# S32R372 register map
Vendor: Freescale Semiconductor, Inc.; Series: Qorivva; File version: 1.6
Registers are 32-bit, read-write, reset 0x0 unless marked. A register's access mark holds for its fields unless they carry their own. Offsets are from the block's base; [hi:lo] are bit positions; {n}, {i} and the like mark numbered series; 'fields as' and 'values as' point back to an identical list.

## MEMU
Base 0xFFF50000; register names take the prefix MEMU_
0x00 CTRL — Control register
  [15] SWR — Software Reset bit
    0=No reset; 1=Reset asserted
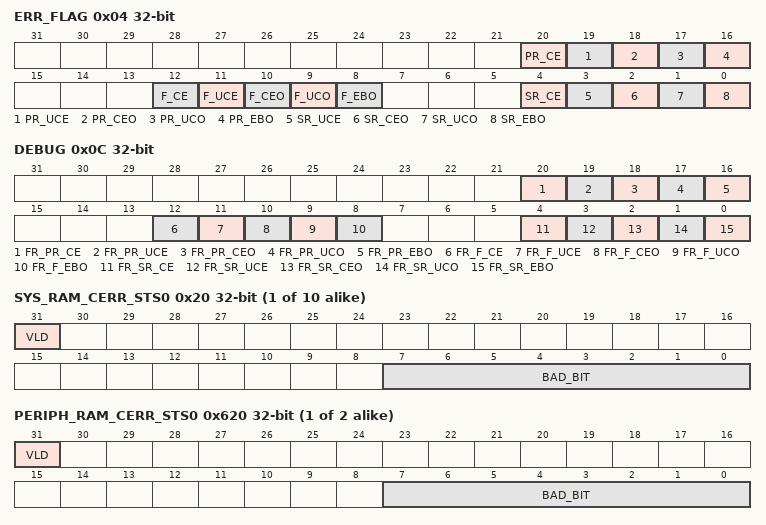
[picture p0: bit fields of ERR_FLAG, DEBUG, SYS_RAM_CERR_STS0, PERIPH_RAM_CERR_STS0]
0x04 ERR_FLAG — Error flag register
  [20] PR_CE — Peripheral RAM ECC Correctable Error detect flag
    0=No new and unique error detected; 1=New entry in correctable error reporting table is made
  [19] PR_UCE — Peripheral RAM ECC Uncorrectable Error Detect flag
    0=No new and unique error detected; 1=New entry in uncorrectable error reporting table is made
  [18] PR_CEO — Peripheral RAM ECC Correctable error Overflow flag
    0=No Overflow; 1=Overflow in the correctable error reporting table detected
  [17] PR_UCO — Peripheral RAM ECC Uncorrectable error Overflow flag
    0=No Overflow; 1=Overflow in the uncorrectable error reporting table detected
  [16] PR_EBO — Peripheral RAM ECC Error buffer Overflow flag
  [12] F_CE — Flash ECC Correctable Error Detect flag
    values as PR_CE
  [11] F_UCE — Flash ECC Uncorrectable Error Detect flag
    values as PR_UCE
  [10] F_CEO — Flash ECC Correctable Error Overflow flag
    values as PR_CEO
  [9] F_UCO — Flash ECC Uncorrectable Error Overflow flag
    values as PR_UCO
  [8] F_EBO — Flash ECC Error buffer Overflow
    0=No Overflow; 1=Overflow in the internal error processing buffer detected
  [4] SR_CE — System RAM ECC Correctable Error detect flag
    values as PR_CE
  [3] SR_UCE — System RAM ECC Uncorrectable Error Detect flag
    values as PR_UCE
  [2] SR_CEO — System RAM ECC Correctable error Overflow flag
    values as PR_CEO
  [1] SR_UCO — System RAM ECC Uncorrectable error Overflow flag
    values as PR_UCO
  [0] SR_EBO — System RAM ECC Error buffer Overflow
    values as F_EBO
0x0C DEBUG
  [20] FR_PR_CE — Force Peripheral RAM Correctable Error detect flag.
    0=Forcing is disabled; 1=Forces PR_CE flag going towards FCCU to 1
  [19] FR_PR_UCE — Force Peripheral RAM Uncorrectable Error detect flag.
    0=Forcing is disabled; 1=Forces PR_UCE flag going towards FCCU to 1
  [18] FR_PR_CEO — Force Peripheral RAM Correctable Error overflow flag
    0=Forcing is disabled; 1=Forces PR_CEO flag going towards FCCU to 1
  [17] FR_PR_UCO — Forces Peripheral RAM Uncorrectable Error overflow flag.
    0=Forcing is disabled; 1=Forces PR_UCO flag going towards FCCU to 1
  [16] FR_PR_EBO — Forces Peripheral RAM Error Buffer Overflow Flag.
    0=Forcing is disabled; 1=Forces PR_EBO flag going towards FCCU to 1
  [12] FR_F_CE — Forces Flash Correctable Error detect flag
    0=Forcing is disabled; 1=Forces F_CE flag going towards FCCU to 1
  [11] FR_F_UCE — Forces Flash Uncorrectable Error detect flag
    0=Forcing is disabled; 1=Forces F_UCE flag going towards FCCU to 1
  [10] FR_F_CEO — Forces Flash Correctable Error overflow flag
    0=Forcing is disabled; 1=Forces F_CEO flag going towards FCCU to 1
  [9] FR_F_UCO — Forces Flash Uncorrectable Error overflow flag
    0=Forcing is disabled; 1=Forces F_UCO flag going towards FCCU to 1
  [8] FR_F_EBO — Forces Flash Error buffer Overflow flag
    0=Forcing is disabled; 1=Forces F_EBO flag going towards FCCU to 1
  [4] FR_SR_CE — Forces System RAM Correctable Error detect flag
    0=Forcing is disabled; 1=Forces SR_CE flag going towards FCCU to 1
  [3] FR_SR_UCE — Forces System RAM Uncorrectable Error detect flag
    0=Forcing is disabled; 1=Forces SR_UCE flag going towards FCCU to 1
  [2] FR_SR_CEO — Forces System RAM Correctable Error overflow flag
    0=Forcing is disabled; 1=Forces SR_CEO flag going towards FCCU to 1
  [1] FR_SR_UCO — Forces System RAM Uncorrectable Error overflow flag
    0=Forcing is disabled; 1=Forces SR_UCO flag going towards FCCU to 1
  [0] FR_SR_EBO — Forces System RAM Error buffer Overflow Flag
    0=Forcing is disabled; 1=Forces SR_EBO flag going towards FCCU to 1
{0x20+8i} SYS_RAM_CERR_STS{i} (i=0..9) — System RAM correctable error reporting table status register
  [31] VLD — Valid bit
    0=Entry in table is invalid; 1=Entry in table is valid
  [7:0] BAD_BIT
{0x24+8i} SYS_RAM_CERR_ADDR{i} (i=0..9) — System RAM correctable error reporting table address register
  [31:0] ERR_ADD — Error address field Indicates the address on which the error was detected.
0x70 SYS_RAM_UNCERR_STS — System RAM uncorrectable error reporting table status register
  [31] VLD — Valid bit
    0=Entry in table is invalid; 1=Entry in table is valid
0x74 SYS_RAM_UNCERR_ADDR — System RAM uncorrectable error reporting table address register
  [31:0] ERR_ADD — Error address field. Indicates the address on which the error was detected.
{0x78+4i} SYS_RAM_OFLW{i} (i=0..1) — System RAM concurrent overflow register
  [31:0] OFLW — Overflow Bit
{0x620+8i} PERIPH_RAM_CERR_STS{i} (i=0..1) — Peripheral RAM correctable error reporting table status register
  fields as SYS_RAM_CERR_STS0
{0x624+8i} PERIPH_RAM_CERR_ADDR{i} (i=0..1) — Peripheral RAM correctable error reporting table address register
  fields as SYS_RAM_CERR_ADDR0
0x630 PERIPH_RAM_UNCERR_STS — Peripheral RAM uncorrectable error reporting table status register
  fields as SYS_RAM_UNCERR_STS
0x634 PERIPH_RAM_UNCERR_ADDR — Peripheral RAM uncorrectable error reporting table address register
  fields as SYS_RAM_UNCERR_ADDR
0x638 PERIPH_RAM_OFLW — Peripheral RAM concurrent overflow register
  [31:0] OFLW — Overflow Bit
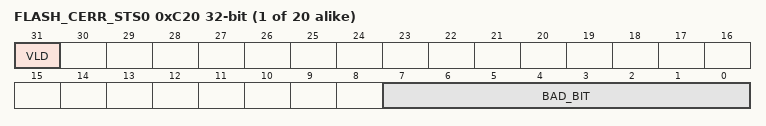
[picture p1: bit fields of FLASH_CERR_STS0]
{0xC20+8i} FLASH_CERR_STS{i} (i=0..19) — Flash memory correctable error reporting table status register
  fields as SYS_RAM_CERR_STS0
{0xC24+8i} FLASH_CERR_ADDR{i} (i=0..19) — Flash memory correctable error reporting table address register
  fields as SYS_RAM_CERR_ADDR0
0xCC0 FLASH_UNCERR_STS — Flash memory uncorrectable error reporting table status register
  fields as SYS_RAM_UNCERR_STS
0xCC4 FLASH_UNCERR_ADDR — Flash memory uncorrectable error reporting table address register
  fields as SYS_RAM_UNCERR_ADDR
0xCC8 FLASH_OFLW — Flash memory concurrent overflow register
  [31:0] OFLW — Overflow Bit
